# nRF7140_graphics register map
Vendor: Nordic Semiconductor; Series: nRF71; File version: 1
CPU: CM33 r0p4, little endian, MPU, FPU, 3 interrupt priority bits, 480 interrupts
Registers are 32-bit, read-write, reset 0x0 unless marked. A register's access mark holds for its fields unless they carry their own. Offsets are from the block's base; [hi:lo] are bit positions; lines under a group give offsets from that group; {n}, {i} and the like mark numbered series; 'fields as' and 'values as' point back to an identical list.

## GLOBAL_STMDATA_NS — System Trace Macrocell data buffer 0
Base 0xA0000000
Same registers: GLOBAL_STMDATA_S 0xA0000000 (alternate view of GLOBAL_STMDATA_NS)
{0x0+0x2000000*i} DOMAIN[{i}] (i=0..15) group — Unspecified
  {0x0+j} NSDATA[{j}] (j=0..16777215) 8-bit — Description collection: NonSecure STM output data buffer for domain n. Writes to this region generates trace packets with id n+96.
  {0x1000000+j} SDATA[{j}] (j=0..16777215) 8-bit — Description collection: Secure STM output data buffer for domain n. Writes to this region generates trace packets with id n+32.
{0x0+0x1000000*i} BUFFER[{i}] (i=0..15) group (alternate view of DOMAIN[{i}]) — Raw buffer access to STM array. Use when DOMAIN array does not apply.
  {0x0+j} DATA[{j}] (j=0..16777215) 8-bit — Description collection: STM output data buffer n. Writes to this region generates trace packets.

## GLOBAL_TDDCONF_NS — TDDCONF 0
Base 0xBF001000
Same registers: GLOBAL_TDDCONF_S 0xBF001000 (alternate view of GLOBAL_TDDCONF_NS)
0x400 SYSPWRUPREQ — System power-up request
  [0] ACTIVE — Activate power-up request
    0=NotActive (Power-up request not active); 1=Active (Power-up request active)
0x404 DBGPWRUPREQ — Debug power-up request
  fields as SYSPWRUPREQ
0x408 TRACEPORTSPEED — Trace port trace clock speed
  [1:0] SPEED — Trace clock speed
    0=Speed80MHz; 1=Speed40MHz; 2=Speed20MHz; 3=Speed10MHz
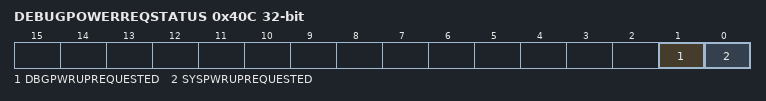
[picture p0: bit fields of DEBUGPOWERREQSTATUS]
0x40C DEBUGPOWERREQSTATUS ro — Combined effective system status of both SWJ-DP and TDDCONF registers originated power requests
  [1] DBGPWRUPREQUESTED — Debug domain powerup request status
    0=NoPowerReq (Power not requested); 1=Power requested
  [0] SYSPWRUPREQUESTED — System powerup request status
    0=NoPowerReq (Power not requested); 1=Power requested

## GLOBAL_TSGEN_NS — GENERIC
Base 0xBF041000
Same registers: GLOBAL_ETB_NS 0xBF044000, GLOBAL_ETR_NS 0xBF045000
0x00 TASKS_GENERICTASK wo — Generic event
  [0] TASKS_GENERICTASK
    1=Trigger task
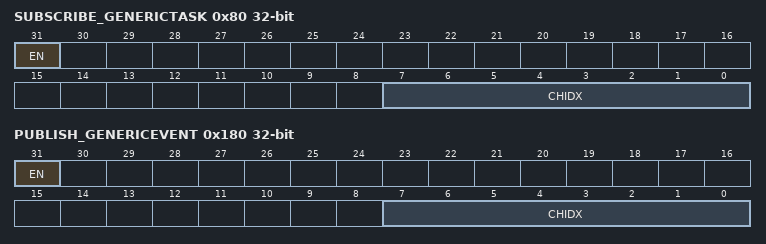
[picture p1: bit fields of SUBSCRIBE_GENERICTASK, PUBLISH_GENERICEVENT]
0x80 SUBSCRIBE_GENERICTASK — Subscribe configuration for task GENERICTASK
  [31] EN
    0=Disabled (Disable subscription); 1=Enabled (Enable subscription)
  [7:0] CHIDX — DPPI channel that task GENERICTASK will subscribe to
0x100 EVENTS_GENERICEVENT — Generic event
  [0] EVENTS_GENERICEVENT
    0=NotGenerated (Event not generated); 1=Generated (Event generated)
0x180 PUBLISH_GENERICEVENT — Publish configuration for event GENERICEVENT
  [31] EN
    0=Disabled (Disable publishing); 1=Enabled (Enable publishing)
  [7:0] CHIDX — DPPI channel that event GENERICEVENT will publish to
0x300 INTEN — Enable or disable interrupt
  [0] GENERICEVENT — Enable or disable interrupt for event GENERICEVENT
    0=Disabled; 1=Enabled
0x304 INTENSET — Enable interrupt
  [0] GENERICEVENT — Write '1' to enable interrupt for event GENERICEVENT
    on read: 0=Disabled (Read: Disabled); 1=Enabled (Read: Enabled) | on write: 1=Set (Enable)
0x308 INTENCLR — Disable interrupt
  [0] GENERICEVENT — Write '1' to disable interrupt for event GENERICEVENT
    on read: 0=Disabled (Read: Disabled); 1=Enabled (Read: Enabled) | on write: 1=Clear (Disable)

## PCGCM0_NS — PCGC Master 0
Base 0x4900F000
Same registers: PCGCM1_NS 0x4901F000
{0xE0+4i} SETPWRCONTHRESHOLDBASE[{i}] (i=0..2) — Description collection: Set power consumption threshold base for power source / regulator n
  [3:0] SETPWRCONTHRESHOLDBASE
{0x100+4i} SETPOWERCONSUMPTIONBASE[{i}] (i=0..1) — Description collection: Set power consumption base for power/clock pair n
  [3:0] POWERREQUIREMENT
0xC00 UNLOCKBACKDOORS
  [15:0] UNLOCKBACKDOORS — Write: 0x00009375 to lock/unlock backdoors Read: 0x00000001 if backdoors is enabled Read: 0x00000000 if backdoors is disabled
0xC04 ENABLEPOWERREGFORCE
  [2:0] ENABLEPOWERREGFORCE
0xC08 POWERREGFORCE — Force reg
  [2:0] POWERREGFORCEREG
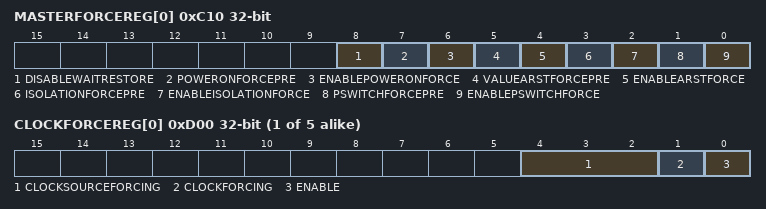
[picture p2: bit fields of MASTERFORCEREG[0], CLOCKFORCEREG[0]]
{0xC10+4i} MASTERFORCEREG[{i}] (i=0..0) — Description collection: Force reg
  [8] DISABLEWAITRESTORE — Turn off waiting for arst deactivation before retention restore
    1=Disable (Turn off waiting for arst deactivation before retention restore); 0=Enable (Wait for arst deactivation before retention restore)
  [7] POWERONFORCEPRE
  [6] ENABLEPOWERONFORCE
  [5] VALUEARSTFORCEPRE
  [4] ENABLEARSTFORCE
  [3] ISOLATIONFORCEPRE
  [2] ENABLEISOLATIONFORCE
  [1] PSWITCHFORCEPRE
  [0] ENABLEPSWITCHFORCE
{0xD00+4i} CLOCKFORCEREG[{i}] (i=0..4) — Description collection: Force clock n
  [4:2] CLOCKSOURCEFORCING
  [1] CLOCKFORCING
  [0] ENABLE — Enable clock forcing
